# EDMACC_0 register map
Vendor: Texas Instruments
Peripheral module from a debugger description file (folder 66AK2G0x_66AK2G1x).
Registers are 32-bit, access per field, reset 0x0 unless marked. A register's access mark holds for its fields unless they carry their own. Offsets are as the file gives them; lines under a group give offsets from that group; [hi:lo] are bit positions; {n}, {i} and the like mark numbered series; 'fields as' and 'values as' point back to an identical list; <NAME> marks a mode.

## EDMACC_0
0x00 EDMACC_PID ro reset 0x4001AB00
  [31:0] PID — TI internal data. Identifies revision of peripheral.
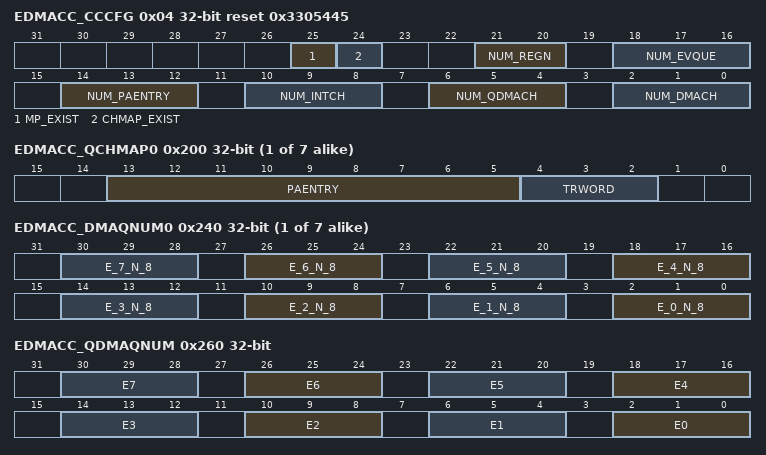
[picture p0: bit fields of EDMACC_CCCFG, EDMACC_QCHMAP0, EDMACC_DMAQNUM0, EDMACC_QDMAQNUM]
0x04 EDMACC_CCCFG ro reset 0x3305445
  [25] MP_EXIST — Memory protection existence.0h = Reserved 1h = Memory protection logic included
  [24] CHMAP_EXIST — Channel mapping existence.0h = Reserved 1h = Channel mapping logic included
  [21:20] NUM_REGN — Number of MP and shadow regions.0h - 2h = Reserved 3h = 8 regions
  [18:16] NUM_EVQUE — Number of queues/number of TCs.0h = Reserved 1h = 2 EDMATCs/Event Queues 2h = Reserved 3h = 4 EDMATCs/Event Queues 4h - 7h = Reserved
  [14:12] NUM_PAENTRY — Number of PaRAM sets.0h - 2h = Reserved 3h = 128 PaRAM sets 4h = Reserved 5h = 512 PaRAM sets 6h - 7h = Reserved
  [10:8] NUM_INTCH — Number of interrupt channels.0h - 1h = Reserved 2h = 16 interrupt channels 3h = Reserved 4h = 64 interrupt channels 5h - 7h = Reserved
  [6:4] NUM_QDMACH — Number of QDMA channels.0h - 3h = Reserved 4h = 8 QDMA channels 5h - 7h = Reserved
  [2:0] NUM_DMACH — Number of DMA channels0h - 2h = Reserved 3h = 16 DMA channels 4h = Reserved 5h = 64 DMA channels 6h - 7h = Reserved
{0x100+4i} EDMACC_DCHMAP{i} (i=0..62)
  [13:5] PAENTRY rw — Points to the PaRAM set number for DMA channeln.
{0x200+4i} EDMACC_QCHMAP{i} (i=0..6)
  [13:5] PAENTRY rw — Points to the PaRAM set number for QDMA channeln. Value = 0-1FFh
  [4:2] TRWORD rw — Points to the specific trigger word of the PaRAM set defined by PAENTRY. A write to the trigger word results in a QDMA event being recognized. Value = 0-7h
{0x240+4i} EDMACC_DMAQNUM{i} (i=0..6)
  [4n+2:4n] E_{n}_N_8 rw (n=0..7) — DMA queue number. Contains the event queue number to be used for the corresponding DMA channel. Programming DMAQNUMN for an event queue number to a value more than the number of queues available in the EDMACC results in undefined behavior. 0h = Event 1h = Event 2h = Event 3h = Event 4h - 7h = Reserved
0x260 EDMACC_QDMAQNUM
  [4n+2:4n] E{n} rw (n=0..7) — QDMA queue number. Contains the event queue number to be used for the corresponding QDMA channel.0h = Event 1h = Event 2h = Event 3h = Event 4h - 7h = Reserved
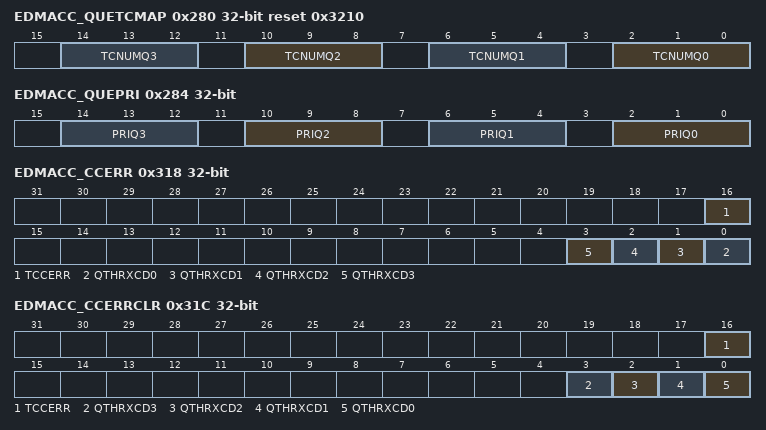
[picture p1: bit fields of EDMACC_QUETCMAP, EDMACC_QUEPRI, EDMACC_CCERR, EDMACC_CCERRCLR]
0x280 EDMACC_QUETCMAP reset 0x3210
  [4n+2:4n] TCNUMQ{n} rw (n=0..3) — TC number for queue {n}. A value of 0 means Q{n} TRs are submitted to TC0 and a value of 3 means Q{n} TRs are submitted to TC3.
0x284 EDMACC_QUEPRI
  [4n+2:4n] PRIQ{n} rw (n=0..3) — Priority level for queue {n}. Dictates the priority level used by TC{n} relative to other masters in the device. A value of 0 means highest priority and a value of 7 means lowest priority.
0x300 EDMACC_EMR ro
  [31:0] EMR31_EMR0 — Channel 31-0 event missed. EN is cleared by writing a 1 to the corresponding bit in the event missed clear register (EDMACC_EMCR). 0h = No missed event. 1h = Missed event occurred.
0x304 EDMACC_EMRH ro
  [31:0] EMR63_EMR32 — Channel 63-32 event missed. EN is cleared by writing a 1 to the corresponding bit in the event missed clear register high (EDMACC_EMCRH). 0h = No missed event. 1h = Missed event occurred.
0x308 EDMACC_EMCR wo
  [31:0] EMCR31_EMCR0 — Event missed 31-0 clear. All error bits must be cleared before additional error interrupts will be asserted by the EDMACC0h = No effect. 1h = Corresponding missed event bit in the event missed register (
0x30C EDMACC_EMCRH wo
  [31:0] EMCR63_EMCR32 — Event missed 32-63 clear. All error bits must be cleared before additional error interrupts will be asserted by the EDMACC.0h = No effect. 1h = Corresponding missed event bit in the event missed register high (
0x310 EDMACC_QEMR ro
  [7:0] QEMR7_QEMR0 — Channel 7-0 QDMA event missed.0h = No missed event. 1h = Missed event occurred.
0x314 EDMACC_QEMCR
  [7:0] QEMCR7_QEMCR0 wo — QDMA event missed clear. All error bits must be cleared before additional error interrupts will be asserted by the EDMACC.0h = No effect. 1h = Corresponding missed event bit in the QDMA event missed register (
0x318 EDMACC_CCERR ro
  [16] TCCERR — Transfer completion code error. TCCERR is cleared by writing a 1 to the corresponding bit in the EDMACC error clear register (EDMACC_CCERRCLR). 0h = Total number of allowed TCCs outstanding has not been reached. 1h = Total number of allowed TCCs has been reached.
  [n] QTHRXCD{n} (n=0..3) — Queue threshold error for queue {n}. QTHRXCD{n} is cleared by writing a 1 to the corresponding bit in the EDMACC error clear register (EDMACC_CCERRCLR). 0h = Watermark/threshold has not been exceeded. 1h = Watermark/threshold has been exceeded.
0x31C EDMACC_CCERRCLR wo
  [16] TCCERR — Transfer completion code error clear0h = No effect. 1h = Clears the TCCERR bit in the EDMACC error register (
  [3] QTHRXCD3 — Queue threshold error clear for queue 3.0h = No effect. 1h = Clears the QTHRXCD3 bit in the EDMACC error register (
  [2] QTHRXCD2 — Queue threshold error clear for queue 2.0h = No effect. 1h = Clears the QTHRXCD2 bit in the EDMACC error register (
  [1] QTHRXCD1 — Queue threshold error clear for queue 1.0h = No effect. 1h = Clears the QTHRXCD1 bit in the EDMACC error register (
  [0] QTHRXCD0 — Queue threshold error clear for queue 0.0h = No effect. 1h = Clears the QTHRXCD0 bit in the EDMACC error register (
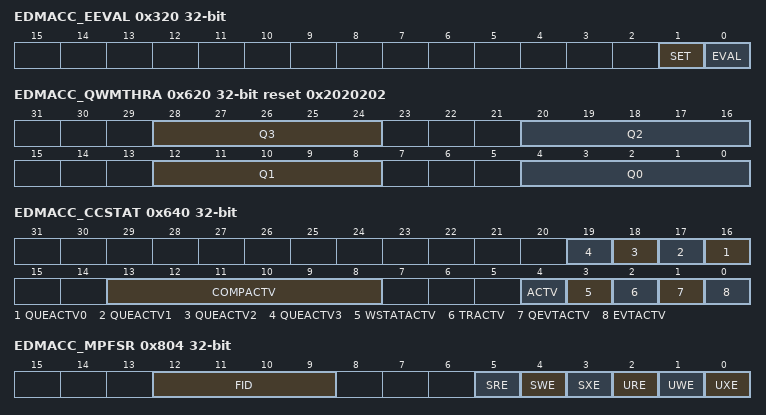
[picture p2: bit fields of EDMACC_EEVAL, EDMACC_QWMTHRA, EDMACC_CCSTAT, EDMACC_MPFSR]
0x320 EDMACC_EEVAL
  [1] SET wo — Always write 0 to this bit; writes of 1 to this bit are not supported and attempts to do so may result in undefined behavior.
  [0] EVAL wo — Error interrupt evaluate.0h = No effect. 1h = EDMACC error interrupt will be pulsed if any errors have not been cleared in any of the error registers (
{0x340+8i} EDMACC_DRAE{i} rw (i=0..7)
  [31:0] DRAE31_DRAE0 — DMA region access enable for bit N/channel N in region{i}. 0h = Accesses via region m address space to bit N in any DMA channel register are not allowed. Reads return 0 on bit N and writes do not modify the state of bit N. Enabled interrupt bits for bit N do not contribute to the generation of a transfer completion interrupt for shadow region 1h = Accesses via region
{0x344+8i} EDMACC_DRAEH{i} rw (i=0..7)
  [31:0] DRAEH31_DRAEH0 — DMA region access enable for bit N/channel N in region{i}. 0h = Accesses via region m address space to bit N in any DMA channel register are not allowed. Reads return 0 on bit N and writes do not modify the state of bit N. Enabled interrupt bits for bit N do not contribute to the generation of a transfer completion interrupt for shadow region 1h = Accesses via region
{0x380+4i} EDMACC_QRAE{i} (i=0..6)
  [7:0] QRAE7_QRAE0 rw — QDMA region access enable for bit N/QDMA channel N in regionm. 0h = Accesses via region 1h = Accesses via region m address space to bit n in any QDMA channel register are allowed. Reads return the value from bit n and writes modify the state of bit N.
0x620 EDMACC_QWMTHRA reset 0x2020202
  [28:24] Q3 rw — Queue threshold for queue 3 value. The QTHRXCD3 bit in the EDMACC error register (EDMACC_CCERR) and the THRXCD bit in the queue status register 3 (EDMACC_QSTAT3) are set when the number of events in queue 3 at an instant in time (visible via the NUMVAL bit in EDMACC_QSTAT3) equals or exceeds the value specified by Q3. 0h- 10h = The default is 16 (maximum allowed). 11h = Disables the threshold errors. 12h - 1Fh = Reserved
  [20:16] Q2 rw — Queue threshold for queue 2 value. The QTHRXCD2 bit in the EDMACC error register (EDMACC_CCERR) and the THRXCD bit in the queue status register 2 (QSTAT2) are set when the number of events in queue 2 at an instant in time (visible via the NUMVAL bit in QSTAT2) equals or exceeds the value specified by Q2. 0h - 10h = The default is 16 (maximum allowed). 11h = Disables the threshold errors. 12h = 1Fh = Reserved
  [12:8] Q1 rw — Queue threshold for queue 1 value. The QTHRXCD1 bit in the EDMACC error register (EDMACC_CCERR) and the THRXCD bit in the queue status register 1 (QSTAT1) are set when the number of events in queue 1 at an instant in time (visible via the NUMVAL bit in QSTAT1) equals or exceeds the value specified by Q1. 0h - 10h =The default is 16 (maximum allowed). 11h = Disables the threshold errors. 12h = 1Fh = Reserved
  [4:0] Q0 rw — Queue threshold for queue 0 value. The QTHRXCD0 bit in the EDMACC error register (EDMACC_CCERR) and the THRXCD bit in the queue status register 0 (EDMACC_QSTAT0) are set when the number of events in queue 0 at an instant in time (visible via the NUMVAL bit in EDMACC_QSTAT0) equals or exceeds the value specified by Q0. 0h - 10h =The default is 16 (maximum allowed). 11h = Disables the threshold errors. 12h = 1Fh = Reserved
0x640 EDMACC_CCSTAT ro
  [n+16] QUEACTV{n} (n=0..3) — Queue {n} active.0h = No events are queued in queue {n}. 1h = At least one TR is queued in queue {n}.
  [13:8] COMPACTV — Completion request active. The COMPACTV field reflects the count for the number of completion requests submitted to the transfer controllers. This count increments every time a TR is submitted and is programmed to report completion (the TCINTEN or TCCCHEN bits in OPT in the parameter entry associated with the TR are set). The counter decrements for every valid TCC received back from the transfer controllers. If at any time the count reaches a value of 63, the EDMACC will not service any new TRs until the count is less then 63 (or return a transfer completion code from a transfer controller, which would decrement the count).0h = No completion requests outstanding. 1h-3Fh = Total of 1 completion request to 63 completion requests are outstanding.
  [4] ACTV — Channel controller active. Channel controller active is a logical-OR of each of the *ACTV bits. The ACTV bit remains high through the life of a TR.0h = Channel is idle. 1h = Channel is busy.
  [3] WSTATACTV — Write status interface active.0h = Write status req is idle and write status FIFO is idle. 1h = Either the write status request is active or additional write status responses are pending in the write status FIFO.
  [2] TRACTV — Transfer request active.0h = Transfer request processing/submission logic is inactive. 1h = Transfer request processing/submission logic is active.
  [1] QEVTACTV — QDMA event active.0h = No enabled QDMA events are active within the EDMACC. 1h = At least one enabled QDMA event (
  [0] EVTACTV — DMA event active.0h = No enabled DMA events are active within the EDMACC. 1h = At least one enabled DMA event (
0x800 EDMACC_MPFAR ro
  [31:0] FADDR — Fault address. This 32-bit read-only status register contains the fault address when a memory protection violation is detected. This register can only be cleared via the memory protection fault command register (EDMACC_MPFCR).
0x804 EDMACC_MPFSR ro
  [12:9] FID — Faulted identification. FID contains valid information if any of the MP error bits (UXE, UWE, URE, SXE, SWE, SRE) are nonzero (that is, if an error has been detected.) The FID field contains the privilege ID for the specific request/requester that resulted in an MP error.
  [5] SRE — Supervisor read error.0h = No error detected. 1h = Supervisor level task attempted to read from a MP page without SR permissions.
  [4] SWE — Supervisor write error.0h = No error detected. 1h = Supervisor level task attempted to write to a MP page without SW permissions.
  [3] SXE — Supervisor execute error.0h = No error detected. 1h = Supervisor level task attempted to execute from a MP page without SX permissions.
  [2] URE — User read error.0h = No error detected. 1h = User level task attempted to read from a MP page without UR permissions.
  [1] UWE — User write error.0h = No error detected. 1h = User level task attempted to write to a MP page without UW permissions.
  [0] UXE — User execute error.0h = No error detected. 1h = User level task attempted to execute from a MP page without UX permissions.
0x808 EDMACC_MPFCR
  [0] MPFCLR wo — Fault clear register.0h = DSP write of 0 has no effect. 1h = DSP write of 1 to the MPFCLR bit causes any error conditions stored in the memory protection fault address register (
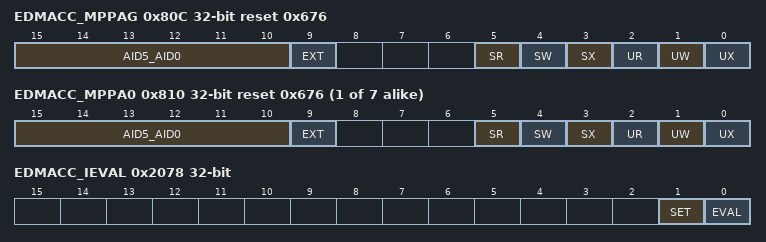
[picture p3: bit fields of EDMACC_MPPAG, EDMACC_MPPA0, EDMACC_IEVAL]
0x80C EDMACC_MPPAG reset 0x676
  [15:10] AID5_AID0 rw — Allowed IDn 0h = Requests with Privilege ID == n are not allowed to region m, regardless of permission settings (UW, UR, SW, SR). 1h = Requests with Privilege ID == n are permitted, if access type is allowed as defined by permission settings (UW, UR, SW, SR).
  [9] EXT rw — External Allowed ID.0h = Requests with Privilege ID &gt;= 6 are not allowed to region m, regardless of permission settings (UW, UR, SW, SR). 1h = Requests with Privilege ID &gt;= 6 are permitted, if access type is allowed as defined by permission settings (UW, UR, SW, SR).
  [5] SR rw — Supervisor read permission0h = Supervisor read accesses are not allowed from region 1h = Supervisor write accesses are allowed from region
  [4] SW rw — Supervisor write permission.0h = Supervisor write accesses are not allowed to region 1h = Supervisor write accesses are allowed to region
  [3] SX rw — Supervisor execute permission.0h = Supervisor execute accesses are not allowed from region 1h = Supervisor execute accesses are allowed from region
  [2] UR rw — User read permission.0h = User read accesses are not allowed from region 1h = User read accesses are allowed from region
  [1] UW rw — User write permission.0h = User write accesses are not allowed to region 1h = User write accesses are allowed to region
  [0] UX rw — User execute permission.0h = User execute accesses are not allowed from region 1h = User execute accesses are allowed from region
{0x810+4i} EDMACC_MPPA{i} reset 0x676 (i=0..6)
  fields as EDMACC_MPPAG
0x2000 EDMACC_ER ro
  [31:0] E31_E0 — Event 31-0. Events 0-31 are captured by the EDMACC and are latched intoEDMACC_ER. The events are set (EN = 1) even when events are disabled (E31-E0 = 0 in the event enable register, EDMACC_EER). 0h = EDMACC event is not asserted. 1h = EDMACC event is asserted. Corresponding DMA event is prioritized versus other pending DMA/QDMA events for submission to the EDMATC.
0x2004 EDMACC_ERH ro
  [31:0] E63_E32 — Event 63-32. Events 32-63 are captured by the EDMACC and are latched intoEDMACC_ERH. The events are set (EN = 1) even when events are disabled (E63-E32 = 0 in the event enable register high, EDMACC_EERH). 0h = EDMACC event is not asserted. 1h = EDMACC event is asserted. Corresponding DMA event is prioritized versus other pending DMA/QDMA events for submission to the EDMATC.
0x2008 EDMACC_ECR wo
  [31:0] E31_E0 — Event clear for event 31-0. Any of the event bits inEDMACC_ECR is set to clear the event (EN) in the event register (EDMACC_ER). A write of 0 has no effect. 0h = No effect. 1h = EDMACC event is cleared in the event register (
0x200C EDMACC_ECRH wo
  [31:0] E63_E32 — Event clear for event 63-32. Any of the event bits inEDMACC_ECRH are set to clear the event (EN) in the event register high (EDMACC_ERH). A write of 0 has no effect. 0h = No effect. 1h = EDMACC event is cleared in the event register high (
0x2010 EDMACC_ESR rw
  [31:0] E31_E0 — Event set for event 31-0.0h = No effect. 1h = Corresponding DMA event is prioritized versus other pending DMA/QDMA events for submission to the EDMATC.
0x2014 EDMACC_ESRH rw
  [31:0] E63_E32 — Event set for event 63-32.0h = No effect. 1h = Corresponding DMA event is prioritized versus other pending DMA/QDMA events for submission to the EDMATC.
0x2018 EDMACC_CER ro
  [31:0] E31_E0 — Chained event for event 31-0.0h = No effect. 1h = Corresponding DMA event is prioritized versus other pending DMA/QDMA events for submission to the EDMATC.
0x201C EDMACC_CERH ro
  [31:0] E63_E32 — Chained event set for event 63-32.0h = No effect. 1h = Corresponding DMA event is prioritized versus other pending DMA/QDMA events for submission to the EDMATC.
0x2020 EDMACC_EER ro
  [31:0] E31_E0 — Event enable for events 31-0.0h = Event is not enabled. An external event latched in the event register ( 1h = Event is enabled. An external event latched in the event register (
0x2024 EDMACC_EERH ro
  [31:0] E63_E32 — Event enable for events 63-32.0h = Event is not enabled. An external event latched in the event register high ( 1h = Event is enabled. An external event latched in the event register high (
0x2028 EDMACC_EECR wo
  [31:0] E31_E0 — Event enable clear for events 31-0.0h = No effect. 1h = Event is disabled. Corresponding bit in the event enable register (
0x202C EDMACC_EECRH wo
  [31:0] E63_E32 — Event enable clear for events 63-32.0h = No effect. 1h = Event is disabled. Corresponding bit in the event enable register high (
0x2030 EDMACC_EESR wo
  [31:0] E31_E0 — Event enable set for events 31-0.0h = No effect. 1h = Event is enabled. Corresponding bit in the event enable register (
0x2034 EDMACC_EESRH wo
  [31:0] E63_E32 — Event enable set for events 63-32.0h = No effect. 1h = Event is enabled. Corresponding bit in the event enable register high (
0x2038 EDMACC_SER ro
  [31:0] SER31_SER0 — Secondary event register. The secondary event register is used along with the event register (EDMACC_ER) to provide information on the state of an event. 0h = Event is not currently stored in the event queue. 1h = Event is currently stored in the event queue. Event arbiter will not prioritize additional events.
0x203C EDMACC_SERH ro
  [31:0] SER63_SER32 — Secondary event register. The secondary event register is used along with the event register high (EDMACC_ERH) to provide information on the state of an event. 0h = Event is not currently stored in the event queue. 1h = Event is currently stored in the event queue. Event submission/prioritization logic will not prioritize additional events.
0x2040 EDMACC_SECR wo
  [31:0] SECR31_SECR0 — Secondary event clear register0h = No effect. 1h = Corresponding bit in the secondary event register (
0x2044 EDMACC_SECRH wo
  [31:0] SECR63_SECR32 — Secondary event clear register.1h = No effect. 2h = Corresponding bit in the secondary event registers high (
0x2050 EDMACC_IER ro
  [31:0] IER31_IER0 — Interrupt enable for channels 31-0.0h = Interrupt is not enabled. 1h = Interrupt is enabled.
0x2054 EDMACC_IERH ro
  [31:0] IER63_IER32 — Interrupt enable for channels 63-32.0h = Interrupt is not enabled. 1h = Interrupt is enabled.
0x2058 EDMACC_IECR wo
  [31:0] IECR31_IECR0 — Interrupt enable clear for channels 31-0.0h = No effect 1h = Corresponding bit in the interrupt enable register (
0x205C EDMACC_IECRH wo
  [31:0] IECR63_IECR32 — Interrupt enable clear for channels 63-32.0h = No effect. 1h = Corresponding bit in the interrupt enable register high (
0x2060 EDMACC_IESR wo
  [31:0] IESR31_IESR0 — Interrupt enable set for channels 31-0.0h = No effect. 1h = Corresponding bit in the interrupt enable register (
0x2064 EDMACC_IESRH wo
  [31:0] IESR63_IESR32 — Interrupt enable clear for channels 63-32.0h = No effect. 1h = Corresponding bit in the interrupt enable register high (
0x2068 EDMACC_IPR ro
  [31:0] IPR31_IPR0 — Interrupt pending for TCC = 31-0.0h = Interrupt transfer completion code is not detected or was cleared. 1h = Interrupt transfer completion code is detected (IN = 1, N = TCC[5:0]).
0x206C EDMACC_IPRH ro
  [31:0] IPR63_IPR32 — Interrupt pending for TCC = 63-32.0h = Interrupt transfer completion code is not detected or was cleared. 1h = Interrupt transfer completion code is detected (IN = 1, N = TCC[5:0]).
0x2070 EDMACC_ICR wo
  [31:0] ICR31_ICR0 — Interrupt clear register for TCC = 31-0.0h = No effect. 1h = Corresponding bit in the interrupt pending register (
0x2074 EDMACC_ICRH wo
  [31:0] ICR63_ICR32 — Interrupt clear register for TCC = 63-32.0h = No effect. 1h = Corresponding bit in the interrupt pending register high (
0x2078 EDMACC_IEVAL
  [1] SET wo — Always write 0. Writes of 1 to this bit are not supported and attempts to do so may result in undefined behavior.
  [0] EVAL wo — Interrupt evaluate0h = No effect. 1h = Causes EDMACC completion interrupt to be pulsed, if any enabled ( The EDMACC completion interrupt that is pulsed depends on which
0x2080 EDMACC_QER ro
  [7:0] QER7_QER0 — QDMA event for channels 7-0.0h = No effect. 1h = Corresponding QDMA event is prioritized versus other pending DMA/QDMA events for submission to the EDMATC.
0x2084 EDMACC_QEER ro
  [7:0] QEER7_QEER0 — QDMA event enable for channels 7-0.0h = QDMA channel N is not enabled. QDMA event is not recognized and is not latched in the QDMA event register ( 1h = QDMA channel N is enabled. QDMA events are recognized and are latched in the QDMA event register (
0x2088 EDMACC_QEECR
  [7:0] QEECR7_QEECR0 wo — QDMA event enable clear for channels 7-0.0h = No effect. 1h = QDMA event is disabled. Corresponding bit in the QDMA event enable register (
0x208C EDMACC_QEESR
  [7:0] QEESR7_QEESR0 wo — QDMA event enable set for channels 7-0.0h = No effect. 1h = QDMA event is enabled. Corresponding bit in the QDMA event enable register (
0x2090 EDMACC_QSER ro
  [7:0] QSER7_QSER0 — QDMA secondary event register for channels 7-0.0h = QDMA event is not currently stored in the event queue. 1h = QDMA event is currently stored in the event queue. EDMACC does not prioritize additional events.
0x2094 EDMACC_QSECR
  [7:0] QSECR7_QSECR0 wo — QDMA secondary event clear for channels 7-0.0h = No effect. 1h = Corresponding bit in the QDMA secondary event register (
